# ESP32-H21 register map
Vendor: ESPRESSIF SYSTEMS (SHANGHAI) CO., LTD.; Series: ESP32 H-Series; File version: 1
CPU: RV32IMAC r0p0, little endian, no MPU, no FPU, 0 interrupt priority bits
Address unit: 32 bits
Registers are 32-bit, read-write, reset 0x0 unless marked. A register's access mark holds for its fields unless they carry their own. Offsets are from the block's base; [hi:lo] are bit positions; {n}, {i} and the like mark numbered series.

## CLINT — Core Local Interrupts
Base 0x20000000
0x1800 MSIP — Core-local machine software interrupt pending register
  [0] MSIP — Configures the pending status of the machine software interrupt.
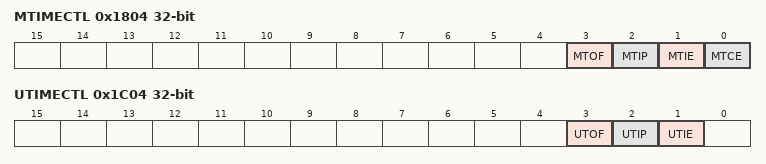
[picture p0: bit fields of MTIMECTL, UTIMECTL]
0x1804 MTIMECTL access per field — Core-local machine timer interrupt control/status register
  [3] MTOF rw — Configures whether the machine timer overflows.
  [2] MTIP ro — Represents the pending status of the machine timer interrupt.
  [1] MTIE rw — Write 1 to enable the machine timer interrupt.
  [0] MTCE rw — Configures whether to enable the CLINT timer counter.
0x1808 MTIME 64-bit (reset mask 0xFFFFFFFF) — Core-local system counter value
  [63:0] MTIME — Configures the 64-bit CLINT timer counter value.
0x1810 MTIMECMP 64-bit (reset mask 0xFFFFFFFF) — Core-local machine timer compare value
  [63:0] MTIMECMP — Configures the 64-bit machine timer compare value.
0x1C00 USIP — Core-local user software interrupt pending register
  [0] USIP — Configures the pending status of the user software interrupt.
0x1C04 UTIMECTL access per field — Core-local user timer interrupt control/status register
  [3] UTOF rw — Configures whether the user timer overflows.
  [2] UTIP ro — Represents the pending status of the user timer interrupt.
  [1] UTIE rw — Write 1 to enable the user timer interrupt.
0x1C08 UTIME 64-bit ro (reset mask 0xFFFFFFFF) — Read-only 64-bit core local timer counter value
  [63:0] UTIME — Represents the read-only 64-bit CLINT timer counter value.
0x1C10 UTIMECMP 64-bit (reset mask 0xFFFFFFFF) — Core-local user timer compare value
  [63:0] UTIMECMP — Configures the 64-bit user timer compare value.

## PLIC_MX — PLIC Peripheral
Base 0x20001000
0x00 MXINT_ENABLE — PLIC MX Interrupt Enable Register
  [31:0] CPU_MXINT_ENABLE
0x04 MXINT_TYPE — PLIC MX Interrupt Type Register
  [31:0] CPU_MXINT_TYPE
0x08 MXINT_CLEAR — PLIC MX Interrupt Clear Register
  [31:0] CPU_MXINT_CLEAR
0x0C EMIP_STATUS ro — PLIC EMIP Status Register
  [31:0] CPU_EIP_STATUS
{0x10+4i} MXINT{i}_PRI (i=0..31) — PLIC MX Interrupt {i} Priority Register
  [3:0] CPU_MXINT_PRI
0x90 MXINT_THRESH — PLIC MX Interrupt Threshold Register
  [7:0] CPU_MXINT_THRESH
0x94 MXINT_CLAIM — PLIC MX Interrupt Claim Register
  [31:0] CPU_MXINT_CLAIM — hp_mb_int is generated after writing 32'h20200721 to core0_lp_intr_flag.
0x3FC MXINT_CONF — PLIC MX Interrupt Configuration Register (PLIC_MXINT_CONF_REG)
  [31:0] CPU_MXINT_CONF

## PLIC_UX — PLIC Peripheral
Base 0x20001400
0x00 UXINT_ENABLE — PLIC UX Interrupt Enable Register
  [31:0] CPU_UXINT_ENABLE
0x04 UXINT_TYPE — PLIC UX Interrupt Type Register
  [31:0] CPU_UXINT_TYPE
0x08 UXINT_CLEAR — PLIC UX Interrupt Clear Register
  [31:0] CPU_UXINT_CLEAR
0x0C EUIP_STATUS ro — PLIC EMIP Status Register
  [31:0] CPU_EIP_STATUS
{0x10+4i} UXINT{i}_PRI (i=0..31) — PLIC UX Interrupt {i} Priority Register
  [3:0] CPU_UXINT_PRI
0x90 UXINT_THRESH — PLIC UX Interrupt Threshold Register
  [7:0] CPU_UXINT_THRESH
0x94 UXINT_CLAIM — PLIC UX Interrupt Claim Register
  [31:0] CPU_UXINT_CLAIM — hp_mb_int is generated after writing 32'h20200721 to core0_lp_intr_flag.
0x3FC UXINT_CONF — PLIC UX Interrupt Configuration Register (PLIC_UXINT_CONF_REG)
  [31:0] CPU_UXINT_CONF

## DS — Digital Signature
Base 0x6008C000
{0x0+4i} Y_MEM[{i}] (i=0..127) access not given — memory that stores Y
{0x200+4i} M_MEM[{i}] (i=0..127) access not given — memory that stores M
{0x400+4i} RB_MEM[{i}] (i=0..127) access not given — memory that stores Rb
{0x600+4i} BOX_MEM[{i}] (i=0..11) access not given — memory that stores BOX
{0x630+4i} IV_MEM[{i}] (i=0..3) access not given — memory that stores IV
{0x800+4i} X_MEM[{i}] (i=0..127) access not given — memory that stores X
{0xA00+4i} Z_MEM[{i}] (i=0..127) access not given — memory that stores Z
0xE00 SET_START wo — DS start control register
  [0] SET_START — set this bit to start DS operation.
0xE04 SET_CONTINUE wo — DS continue control register
  [0] SET_CONTINUE — set this bit to continue DS operation.
0xE08 SET_FINISH wo — DS finish control register
  [0] SET_FINISH — Set this bit to finish DS process.
0xE0C QUERY_BUSY ro — DS query busy register
  [0] QUERY_BUSY — digital signature state. 1'b0: idle, 1'b1: busy
0xE10 QUERY_KEY_WRONG ro — DS query key-wrong counter register
  [3:0] QUERY_KEY_WRONG — digital signature key wrong counter
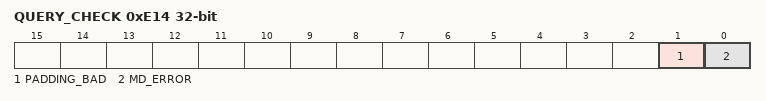
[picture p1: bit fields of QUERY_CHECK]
0xE14 QUERY_CHECK ro — DS query check result register
  [1] PADDING_BAD — padding checkout result. 1'b0: a good padding, 1'b1: a bad padding
  [0] MD_ERROR — MD checkout result. 1'b0: MD check pass, 1'b1: MD check fail
0xE20 DATE — DS version control register

## Notices in the file
Copyright 2026 Espressif Systems (Shanghai) PTE LTD
Licensed under the Apache License, Version 2.0 (the "License");
you may not use this file except in compliance with the License.
You may obtain a copy of the License at
http://www.apache.org/licenses/LICENSE-2.0
Unless required by applicable law or agreed to in writing, software
distributed under the License is distributed on an "AS IS" BASIS,
WITHOUT WARRANTIES OR CONDITIONS OF ANY KIND, either express or implied.
See the License for the specific language governing permissions and
limitations under the License.
